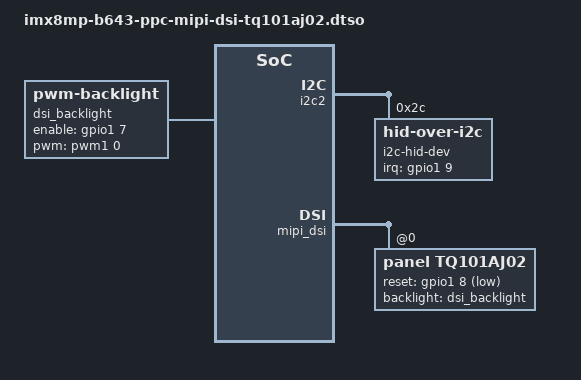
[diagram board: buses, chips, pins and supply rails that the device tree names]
// SPDX-License-Identifier: (GPL-2.0+ OR MIT)
/*
 * Copyright 2026 Jason Yang <jasonyang@ieiworld.com>
 */

#include <dt-bindings/gpio/gpio.h>
#include <dt-bindings/pwm/pwm.h>
#include <dt-bindings/interrupt-controller/irq.h>
#include "imx8mp-pinfunc.h"

/dts-v1/;
/plugin/;

&{/} {
	dsi_backlight: dsi_backlight {
		compatible = "pwm-backlight";
		pwms = <&pwm1 0 66667>;
		enable-gpios = <&gpio1 7 GPIO_ACTIVE_HIGH>;

		brightness-levels = < 0  1  2  3  4  5  6  7
			  8   9  10  11  12  13  14  15
			 16  17  18  19  20  21  22  23
			 24  25  26  27  28  29  30  31
			 32  33  34  35  36  37  38  39
			 40  41  42  43  44  45  46  47
			 48  49  50  51  52  53  54  55
			 56  57  58  59  60  61  62  63
			 64  65  66  67  68  69  70  71
			 72  73  74  75  76  77  78  79
			 80  81  82  83  84  85  86  87
			 88  89  90  91  92  93  94  95
			 96  97  98  99 100 101 102 103
			104 105 106 107 108 109 110 111
			112 113 114 115 116 117 118 119
			120 121 122 123 124 125 126 127
			128 129 130 131 132 133 134 135
			136 137 138 139 140 141 142 143
			144 145 146 147 148 149 150 151
			152 153 154 155 156 157 158 159
			160 161 162 163 164 165 166 167
			168 169 170 171 172 173 174 175
			176 177 178 179 180 181 182 183
			184 185 186 187 188 189 190 191
			192 193 194 195 196 197 198 199
			200 201 202 203 204 205 206 207
			208 209 210 211 212 213 214 215
			216 217 218 219 220 221 222 223
			224 225 226 227 228 229 230 231
			232 233 234 235 236 237 238 239
			240 241 242 243 244 245 246 247
			248 249 250 251 252 253 254 255>;
		default-brightness-level = <200>;

		status = "okay";
	};
};

&i2c2 {
	#address-cells = <1>;
	#size-cells = <0>;

	i2c-hid-dev@2c {
		compatible = "hid-over-i2c";
		reg = <0x2c>;
		hid-descr-addr = <0x0020>;
		pinctrl-names = "default";
		pinctrl-0 = <&pinctrl_touch_irq>;
		interrupt-parent = <&gpio1>;
		interrupts = <9 IRQ_TYPE_LEVEL_LOW>;
		status = "okay";
	};
};

&mipi_dsi {
	#address-cells = <1>;
	#size-cells = <0>;
	status = "okay";

	panel@0 {
		compatible = "panel,tq101aj02";
		reg = <0>;
		backlight = <&dsi_backlight>;
		pinctrl-0 = <&pinctrl_mipi_dsi_en>;
		reset-gpio = <&gpio1 8 GPIO_ACTIVE_LOW>;
		dsi-lanes = <4>;
		video-mode = <2>;	/* 0: burst mode
					 * 1: non-burst mode with sync event
					 * 2: non-burst mode with sync pulse
					 */
		panel-width-mm = <135>;
		panel-height-mm = <216>;
		status = "okay";
	};
};

&iomuxc {
	pinctrl_mipi_dsi_en: mipi_dsi_en {
		fsl,pins = <
			MX8MP_IOMUXC_GPIO1_IO07__GPIO1_IO07	0x16
			MX8MP_IOMUXC_GPIO1_IO08__GPIO1_IO08	0x16
		>;
	};

	pinctrl_touch_irq: touch_irqgrp {
		fsl,pins = <
			MX8MP_IOMUXC_GPIO1_IO09__GPIO1_IO09	0x16
		>;
	};
};
